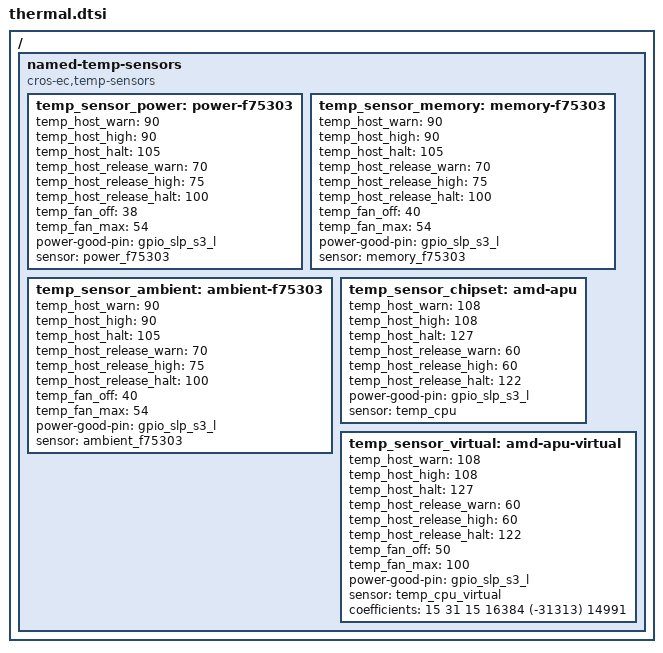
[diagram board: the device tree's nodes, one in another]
/* Copyright 2024 The ChromiumOS Authors
 * Use of this source code is governed by a BSD-style license that can be
 * found in the LICENSE file.
 */

/ {
	named-temp-sensors {
		compatible = "cros-ec,temp-sensors";
		/* Uth1 */
		temp_sensor_power: power-f75303 {
			temp_host_warn = <90>;
			temp_host_high = <90>;
			temp_host_halt = <105>;
			temp_host_release_warn = <70>;
			temp_host_release_high = <75>;
			temp_host_release_halt = <100>;
			temp_fan_off = <38>;
			temp_fan_max = <54>;
			power-good-pin = <&gpio_slp_s3_l>;
			sensor = <&power_f75303>;
		};
		/* Qth1 */
		temp_sensor_memory: memory-f75303 {
			temp_host_warn = <90>;
			temp_host_high = <90>;
			temp_host_halt = <105>;
			temp_host_release_warn = <70>;
			temp_host_release_high = <75>;
			temp_host_release_halt = <100>;
			temp_fan_off = <40>;
			temp_fan_max = <54>;
			power-good-pin = <&gpio_slp_s3_l>;
			sensor = <&memory_f75303>;
		};
		/* Qth2 */
		temp_sensor_ambient: ambient-f75303 {
			temp_host_warn = <90>;
			temp_host_high = <90>;
			temp_host_halt = <105>;
			temp_host_release_warn = <70>;
			temp_host_release_high = <75>;
			temp_host_release_halt = <100>;
			temp_fan_off = <40>;
			temp_fan_max = <54>;
			power-good-pin = <&gpio_slp_s3_l>;
			sensor = <&ambient_f75303>;
		};
		temp_sensor_chipset: amd-apu {
			temp_host_warn = <108>;
			temp_host_high = <108>;
			temp_host_halt = <127>;
			temp_host_release_warn = <60>;
			temp_host_release_high = <60>;
			temp_host_release_halt = <122>;
			power-good-pin = <&gpio_slp_s3_l>;
			sensor = <&temp_cpu>;
		};

		temp_sensor_virtual: amd-apu-virtual {
			temp_host_warn = <108>;
			temp_host_high = <108>;
			temp_host_halt = <127>;
			temp_host_release_warn = <60>;
			temp_host_release_high = <60>;
			temp_host_release_halt = <122>;
			temp_fan_off = <50>;
			temp_fan_max = <100>;
			power-good-pin = <&gpio_slp_s3_l>;
			sensor = <&temp_cpu_virtual>;
			coefficients = <15 31 15 16384 (-31313) 14991>;
		};
	};
};
